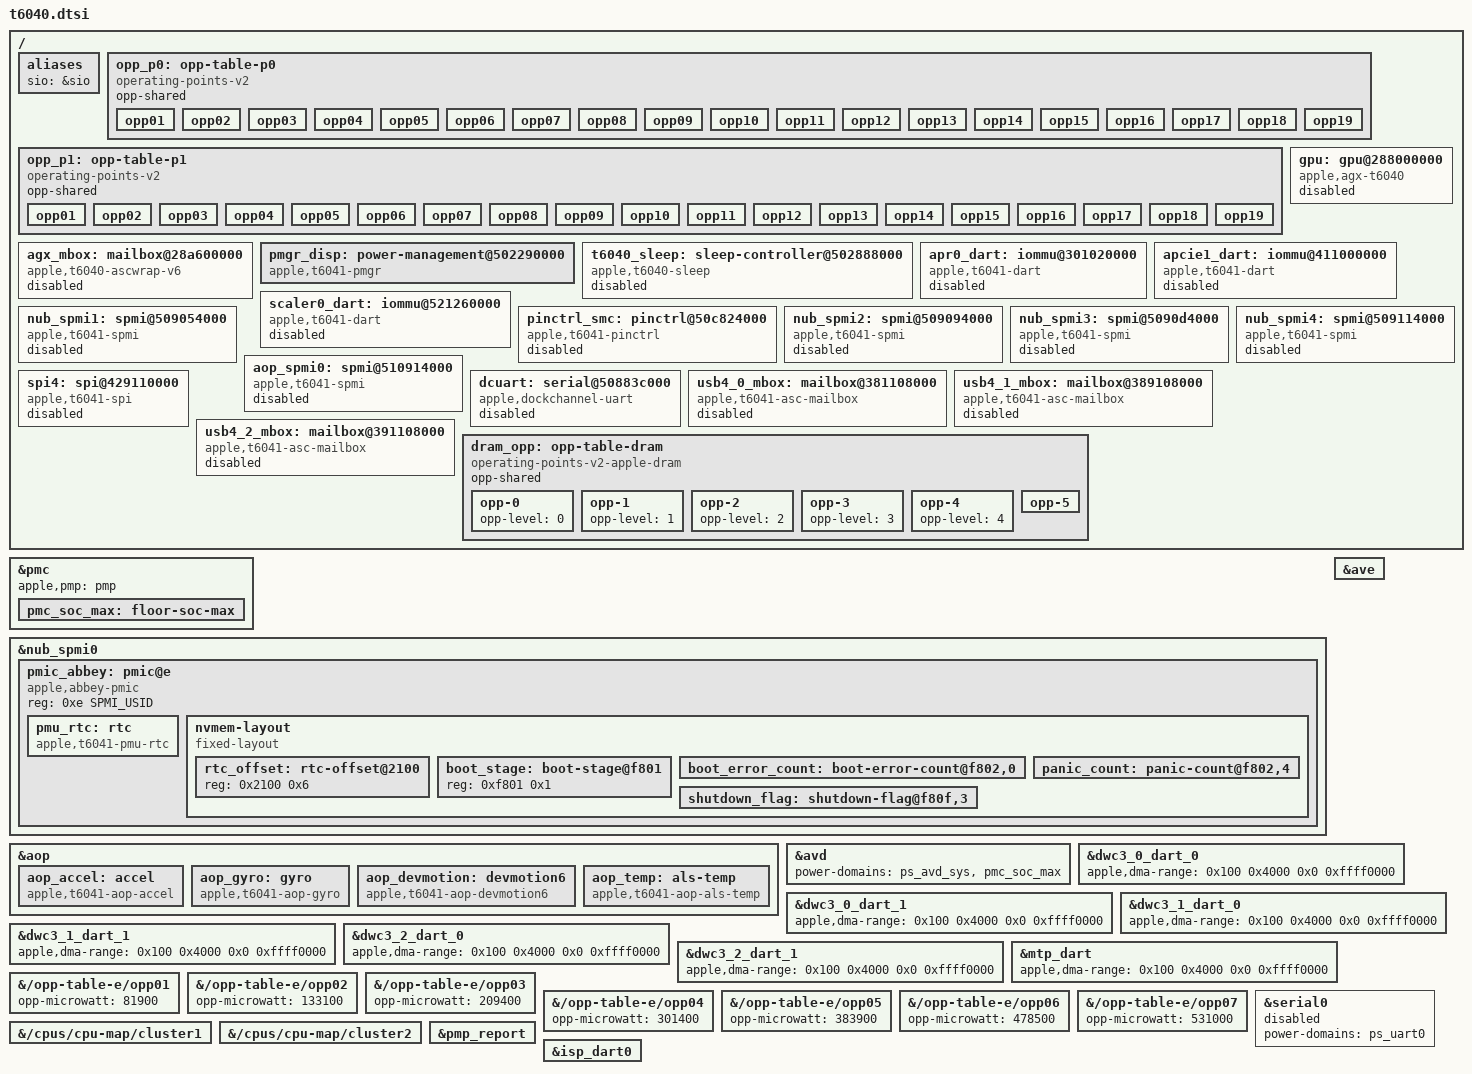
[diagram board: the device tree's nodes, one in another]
// SPDX-License-Identifier: GPL-2.0+ OR MIT
/*
 * Apple T6040 "M4 Pro" SoC
 *
 * Copyright The Asahi Linux Contributors
 */

#include "t604x.dtsi"

/* Blocks and properties the T6041 tree does not describe yet. */
/ {
	aliases {
		sio = &sio;
	};

	opp_p0: opp-table-p0 {
		compatible = "operating-points-v2";
		opp-shared;

		opp01 {
			opp-hz = /bits/ 64 <1260000000>;
			opp-level = <1>;
			opp-microwatt = <513000>;
		};
		opp02 {
			opp-hz = /bits/ 64 <1512000000>;
			opp-level = <2>;
			opp-microwatt = <715000>;
		};
		opp03 {
			opp-hz = /bits/ 64 <1800000000>;
			opp-level = <3>;
			opp-microwatt = <907500>;
		};
		opp04 {
			opp-hz = /bits/ 64 <2088000000>;
			opp-level = <4>;
			opp-microwatt = <1158200>;
		};
		opp05 {
			opp-hz = /bits/ 64 <2352000000>;
			opp-level = <5>;
			opp-microwatt = <1494500>;
		};
		opp06 {
			opp-hz = /bits/ 64 <2616000000>;
			opp-level = <6>;
			opp-microwatt = <1782600>;
		};
		opp07 {
			opp-hz = /bits/ 64 <2868000000>;
			opp-level = <7>;
			opp-microwatt = <2209600>;
		};
		opp08 {
			opp-hz = /bits/ 64 <3096000000>;
			opp-level = <8>;
			opp-microwatt = <2636700>;
		};
		opp09 {
			opp-hz = /bits/ 64 <3300000000>;
			opp-level = <9>;
			opp-microwatt = <3247200>;
		};
		opp10 {
			opp-hz = /bits/ 64 <3468000000>;
			opp-level = <10>;
			opp-microwatt = <3668700>;
		};
		opp11 {
			opp-hz = /bits/ 64 <3624000000>;
			opp-level = <11>;
			opp-microwatt = <4128200>;
		};
		opp12 {
			opp-hz = /bits/ 64 <3756000000>;
			opp-level = <12>;
			opp-microwatt = <4819300>;
		};
		opp13 {
			opp-hz = /bits/ 64 <3852000000>;
			opp-level = <13>;
			opp-microwatt = <4977700>;
		};
		opp14 {
			opp-hz = /bits/ 64 <3924000000>;
			opp-level = <14>;
			opp-microwatt = <5315900>;
		};
		opp15 {
			opp-hz = /bits/ 64 <3996000000>;
			opp-level = <15>;
			opp-microwatt = <5575900>;
		};
		opp16 {
			opp-hz = /bits/ 64 <4044000000>;
			opp-level = <16>;
			opp-microwatt = <5773400>;
		};
		opp17 {
			opp-hz = /bits/ 64 <4104000000>;
			opp-level = <17>;
			opp-microwatt = <5969200>;
		};
		opp18 {
			opp-hz = /bits/ 64 <4416000000>;
			opp-level = <18>;
			opp-microwatt = <8274900>;
		};
		opp19 {
			opp-hz = /bits/ 64 <4512000000>;
			opp-level = <19>;
			opp-microwatt = <9256900>;
		};
	};

	opp_p1: opp-table-p1 {
		compatible = "operating-points-v2";
		opp-shared;

		opp01 {
			opp-hz = /bits/ 64 <1260000000>;
			opp-level = <1>;
			opp-microwatt = <561800>;
		};
		opp02 {
			opp-hz = /bits/ 64 <1512000000>;
			opp-level = <2>;
			opp-microwatt = <772500>;
		};
		opp03 {
			opp-hz = /bits/ 64 <1800000000>;
			opp-level = <3>;
			opp-microwatt = <988900>;
		};
		opp04 {
			opp-hz = /bits/ 64 <2088000000>;
			opp-level = <4>;
			opp-microwatt = <1302300>;
		};
		opp05 {
			opp-hz = /bits/ 64 <2352000000>;
			opp-level = <5>;
			opp-microwatt = <1644100>;
		};
		opp06 {
			opp-hz = /bits/ 64 <2616000000>;
			opp-level = <6>;
			opp-microwatt = <2003700>;
		};
		opp07 {
			opp-hz = /bits/ 64 <2868000000>;
			opp-level = <7>;
			opp-microwatt = <2349000>;
		};
		opp08 {
			opp-hz = /bits/ 64 <3096000000>;
			opp-level = <8>;
			opp-microwatt = <2723000>;
		};
		opp09 {
			opp-hz = /bits/ 64 <3300000000>;
			opp-level = <9>;
			opp-microwatt = <3333200>;
		};
		opp10 {
			opp-hz = /bits/ 64 <3468000000>;
			opp-level = <10>;
			opp-microwatt = <3711900>;
		};
		opp11 {
			opp-hz = /bits/ 64 <3624000000>;
			opp-level = <11>;
			opp-microwatt = <4129900>;
		};
		opp12 {
			opp-hz = /bits/ 64 <3756000000>;
			opp-level = <12>;
			opp-microwatt = <4666300>;
		};
		opp13 {
			opp-hz = /bits/ 64 <3852000000>;
			opp-level = <13>;
			opp-microwatt = <4881000>;
		};
		opp14 {
			opp-hz = /bits/ 64 <3924000000>;
			opp-level = <14>;
			opp-microwatt = <5176700>;
		};
		opp15 {
			opp-hz = /bits/ 64 <3996000000>;
			opp-level = <15>;
			opp-microwatt = <5306500>;
		};
		opp16 {
			opp-hz = /bits/ 64 <4044000000>;
			opp-level = <16>;
			opp-microwatt = <5618900>;
		};
		opp17 {
			opp-hz = /bits/ 64 <4104000000>;
			opp-level = <17>;
			opp-microwatt = <5843100>;
		};
		opp18 {
			opp-hz = /bits/ 64 <4416000000>;
			opp-level = <18>;
			opp-microwatt = <8075300>;
		};
		opp19 {
			opp-hz = /bits/ 64 <4512000000>;
			opp-level = <19>;
			opp-microwatt = <8949200>;
		};
	};

	/* Named after its sgx range: the coprocessor range is the mailbox node's too. */
	gpu: gpu@288000000 {
		compatible = "apple,agx-t6040";
		reg = <0x2 0x8a600000 0x0 0x88000>,
		      <0x2 0x88000000 0x0 0x3758000>;
		reg-names = "asc", "sgx";
		mboxes = <&agx_mbox>;
		power-domains = <&pmp_gfx>;
		apple,clpc = <&clpc>;
		status = "disabled";
	};

	agx_mbox: mailbox@28a600000 {
		compatible = "apple,t6040-ascwrap-v6";
		reg = <0x2 0x8a600000 0x0 0x88000>,
		      <0x2 0x8a050000 0x0 0x8>;
		reg-names = "wrapper", "iop-vbar";
		interrupt-parent = <&aic>;
		interrupts = <AIC_IRQ 1501 IRQ_TYPE_LEVEL_HIGH>,
			     <AIC_IRQ 1504 IRQ_TYPE_LEVEL_HIGH>;
		interrupt-names = "send-empty", "recv-not-empty";
		apple,firmware-role = "GFX";
		power-domains = <&ps_gfx>;
		#mbox-cells = <0>;
		status = "disabled";
	};

	pmgr_disp: power-management@502290000 {
		compatible = "apple,t6041-pmgr", "apple,t8103-pmgr", "syscon", "simple-mfd";
		reg = <0x5 0x02290000 0x0 0x4000>;
		/* DISP_CPU's power word takes non-posted accesses (nGnRnE). */
		nonposted-mmio;
		#address-cells = <1>;
		#size-cells = <1>;
	};

	t6040_sleep: sleep-controller@502888000 {
		compatible = "apple,t6040-sleep";
		/*
		 * The SoC blocks the commit and wake
		 * write, all shared read/write with their owning drivers and
		 * touched only once no blocker remains:
		 *   cpu-start   pmgr reg0 + 0x88000 (misc-cores): CPU start/stop
		 *   wdt         the AON watchdog, the sleep's WD2 safety net
		 *   cluster     0x502820000: the three CPU complexes E/P0/P1
		 *   pwrgate     0x50282c000: wake + CPM retention voters
		 *   clkgen      0x500000000: the clk-mux park words
		 *   spmi        0x509014000: the PMU boot-stage + NOTIFY + go-hib
		 *   spmi-a0     0x509188000: the second SPMI NOTIFY
		 *   mastermini  0x508900000: the S2R timer at +0x4000 (the commit)
		 *   soc-east    0x502280000: SOC-East page, retention + east power words
		 *   soc-ps      0x502800000: SOC page, the west axi2af power words
		 *   wake        0x508004000: the S2R control + wake masks/status
		 * The handler refuses before touching any of them.
		 */
		reg = <0x5 0x02888000 0x0 0x20>,
		      <0x5 0x0836c000 0x0 0x4000>,
		      <0x5 0x02820000 0x0 0x20>,
		      <0x5 0x0282c000 0x0 0x1000>,
		      <0x5 0x00000000 0x0 0x80000>,
		      <0x5 0x09014000 0x0 0x1000>,
		      <0x5 0x09188000 0x0 0x1000>,
		      <0x5 0x08900000 0x0 0x8000>,
		      <0x5 0x02280000 0x0 0xd000>,
		      <0x5 0x02800000 0x0 0x9000>,
		      <0x5 0x08004000 0x0 0x1000>;
		reg-names = "cpu-start", "wdt", "cluster", "pwrgate",
			    "clkgen", "spmi", "spmi-a0", "mastermini",
			    "soc-east", "soc-ps", "wake";
		/*
		 * ADT pmgr device-check-ps-b4-sleep (check-ps-b4-sleep = 0x1f): per
		 * display pipe its CPU and its last sub-block, 8 bytes apart.
		 */
		apple,check-ps-b4-sleep = <&pmgr_disp 0x0 0x58>, <&pmgr_aux 0x350 0x388>,
					  <&pmgr_aux 0x4a0 0x4d8>, <&pmgr_aux 0x4f0 0x528>,
					  <&pmgr_aux 0x2e8 0x320>;
		apple,check-ps-b4-sleep-names = "disp", "dispext0", "dispext1", "dispext2",
						"dispext3";
		/*
		 * apple,apcie, for the sleep of ANS's storage PCIe link (two ST lanes
		 * and a shared PHY), comes from the boot loader. From the ADT's
		 * /arm-io/apcie0 it adds it here and puts the axi2af, cio3pll, clkgen,
		 * phy-block and phy-ip windows and the apple,tunable-* arrays on the
		 * internal PCIe host (apple,t6020-pcie, the one with an "rc"
		 * reg-name), in the single-lane T8140 shape. It leaves a node that
		 * already has apple,apcie alone, so this tree must give neither
		 * apple,apcie nor an apcie-storage node. Without it a sleep with ANS
		 * stopped is refused, and suspend-to-idle stays the default. The ST
		 * power words (ps_ans, ps_apcie_st0/st1, ps_apcie_sys_st0/st1) are in
		 * SOC-East and are driven through the soc-east window.
		 */
		/* Only on a board whose sleep has been tested. */
		status = "disabled";
	};
};

&pmc {
	/*
	 * The SoC rail at its highest state. The video encoder runs on
	 * the fabric clock and encodes at less than half speed below it.
	 */
	pmc_soc_max: floor-soc-max {
		label = "soc-max";
		#power-domain-cells = <0>;
		apple,rail = <1>;
		apple,level = <2>;
	};
};

&nub_spmi0 {
	pmic_abbey: pmic@e {
		compatible = "apple,abbey-pmic", "apple,spmi-nvmem";
		reg = <0xe SPMI_USID>;

		pmu_rtc: rtc {
			compatible = "apple,t6041-pmu-rtc";
			interrupt-parent = <&nub_spmi0>;
			interrupts = <2 IRQ_TYPE_EDGE_RISING>;
			nvmem-cells = <&rtc_offset>;
			nvmem-cell-names = "rtc_offset";
			wakeup-source;
		};

		nvmem-layout {
			compatible = "fixed-layout";
			#address-cells = <1>;
			#size-cells = <1>;

			rtc_offset: rtc-offset@2100 {
				reg = <0x2100 0x6>;
			};

			boot_stage: boot-stage@f801 {
				reg = <0xf801 0x1>;
			};

			boot_error_count: boot-error-count@f802,0 {
				reg = <0xf802 0x1>;
				bits = <0 4>;
			};

			panic_count: panic-count@f802,4 {
				reg = <0xf802 0x1>;
				bits = <4 4>;
			};

			shutdown_flag: shutdown-flag@f80f,3 {
				reg = <0xf80f 0x1>;
				bits = <3 1>;
			};
		};
	};
};

&aop {
	/* The calibration properties come from the bootloader. */
	aop_accel: accel {
		compatible = "apple,t6041-aop-accel", "apple,aop-accel";
	};

	aop_gyro: gyro {
		compatible = "apple,t6041-aop-gyro", "apple,aop-gyro";
	};

	aop_devmotion: devmotion6 {
		compatible = "apple,t6041-aop-devmotion6", "apple,aop-devmotion6";
	};

	aop_temp: als-temp {
		compatible = "apple,t6041-aop-als-temp", "apple,aop-als-temp";
	};
};

/ {
	apr0_dart: iommu@301020000 {
		compatible = "apple,t6041-dart", "apple,t8110-dart";
		reg = <0x3 0x01020000 0x0 0xc000>;
		#iommu-cells = <1>;
		apple,dma-range = <0x100 0x0 0x300 0x0>;
		interrupt-parent = <&aic>;
		interrupts = <AIC_IRQ 1959 IRQ_TYPE_LEVEL_HIGH>;
		power-domains = <&ps_scodec>;
		status = "disabled";
	};

	apcie1_dart: iommu@411000000 {
		compatible = "apple,t6041-dart", "apple,t8110-dart";
		reg = <0x4 0x11000000 0x0 0x20000>;
		#iommu-cells = <1>;
		interrupt-parent = <&aic>;
		interrupts = <AIC_IRQ 1733 IRQ_TYPE_LEVEL_HIGH>;
		status = "disabled";
	};

	scaler0_dart: iommu@521260000 {
		compatible = "apple,t6041-dart", "apple,t8110-dart";
		reg = <0x5 0x21260000 0x0 0xc000>;
		#iommu-cells = <1>;
		apple,dma-range = <0x100 0x0 0x300 0x0>;
		interrupt-parent = <&aic>;
		interrupts = <AIC_IRQ 1548 IRQ_TYPE_LEVEL_HIGH>;
		power-domains = <&ps_msr0_dart>;
		status = "disabled";
	};

	pinctrl_smc: pinctrl@50c824000 {
		compatible = "apple,t6041-pinctrl", "apple,t8103-pinctrl";
		reg = <0x5 0x0c824000 0x0 0x4000>;
		clocks = <&clkref>;
		gpio-controller;
		#gpio-cells = <2>;
		gpio-ranges = <&pinctrl_smc 0 0 24>;
		apple,npins = <24>;
		interrupt-controller;
		#interrupt-cells = <2>;
		interrupt-parent = <&aic>;
		interrupts = <AIC_IRQ 985 IRQ_TYPE_LEVEL_HIGH>,
			     <AIC_IRQ 986 IRQ_TYPE_LEVEL_HIGH>,
			     <AIC_IRQ 987 IRQ_TYPE_LEVEL_HIGH>,
			     <AIC_IRQ 988 IRQ_TYPE_LEVEL_HIGH>,
			     <AIC_IRQ 989 IRQ_TYPE_LEVEL_HIGH>,
			     <AIC_IRQ 990 IRQ_TYPE_LEVEL_HIGH>,
			     <AIC_IRQ 991 IRQ_TYPE_LEVEL_HIGH>;
		/* Coprocessor pins and interrupt groups need an ownership handoff. */
		status = "disabled";
	};

	nub_spmi1: spmi@509054000 {
		compatible = "apple,t6041-spmi", "apple,t8103-spmi";
		reg = <0x5 0x09054000 0x0 0x100>;
		#address-cells = <2>;
		#size-cells = <0>;
		power-domains = <&ps_nub_spmi1>;
		status = "disabled";
	};

	nub_spmi2: spmi@509094000 {
		compatible = "apple,t6041-spmi", "apple,t8103-spmi";
		reg = <0x5 0x09094000 0x0 0x100>;
		#address-cells = <2>;
		#size-cells = <0>;
		power-domains = <&ps_nub_spmi2>;
		status = "disabled";
	};

	nub_spmi3: spmi@5090d4000 {
		compatible = "apple,t6041-spmi", "apple,t8103-spmi";
		reg = <0x5 0x090d4000 0x0 0x100>;
		#address-cells = <2>;
		#size-cells = <0>;
		power-domains = <&ps_nub_spmi3>;
		status = "disabled";
	};

	nub_spmi4: spmi@509114000 {
		compatible = "apple,t6041-spmi", "apple,t8103-spmi";
		reg = <0x5 0x09114000 0x0 0x100>;
		#address-cells = <2>;
		#size-cells = <0>;
		power-domains = <&ps_nub_spmi4>;
		status = "disabled";
	};

	aop_spmi0: spmi@510914000 {
		compatible = "apple,t6041-spmi", "apple,t8103-spmi";
		reg = <0x5 0x10914000 0x0 0x100>;
		#address-cells = <2>;
		#size-cells = <0>;
		#interrupt-cells = <2>;
		interrupt-controller;
		interrupt-parent = <&aic>;
		interrupts = <AIC_IRQ 738 IRQ_TYPE_LEVEL_HIGH>;
		status = "disabled";
	};

	spi4: spi@429110000 {
		compatible = "apple,t6041-spi", "apple,t8103-spi";
		reg = <0x4 0x29110000 0x0 0x4000>;
		interrupt-parent = <&aic>;
		interrupts = <AIC_IRQ 1571 IRQ_TYPE_LEVEL_HIGH>;
		clocks = <&clkref>;
		power-domains = <&ps_spi4>;
		#address-cells = <1>;
		#size-cells = <0>;
		/* Panel/TCON control belongs to the display firmware. */
		status = "disabled";
	};

	/*
	 * The DebugUSB DockChannel serial channel. Binding it disturbs the
	 * speaker amplifiers (I2C timeouts, TDM clock faults), so it stays
	 * disabled outside the tether variant.
	 */
	dcuart: serial@50883c000 {
		compatible = "apple,dockchannel-uart";
		reg = <0x5 0x0883c000 0x0 0x4000>,
		      <0x5 0x08838000 0x0 0x4000>,
		      <0x5 0x0880c000 0x0 0x4000>;
		reg-names = "data", "config", "irq";
		interrupt-parent = <&aic>;
		interrupts = <AIC_IRQ 360 IRQ_TYPE_LEVEL_HIGH>;
		apple,channel = <2>;
		apple,sw-drain;
		status = "disabled";
	};

	/* ACIO 0 remains disabled until its host-router handoff is supported. */
	usb4_0_mbox: mailbox@381108000 {
		compatible = "apple,t6041-asc-mailbox", "apple,asc-mailbox-v4";
		reg = <0x3 0x81108000 0x0 0x4000>;
		interrupt-parent = <&aic>;
		interrupts = <AIC_IRQ 934 IRQ_TYPE_LEVEL_HIGH>,
			     <AIC_IRQ 935 IRQ_TYPE_LEVEL_HIGH>,
			     <AIC_IRQ 936 IRQ_TYPE_LEVEL_HIGH>,
			     <AIC_IRQ 937 IRQ_TYPE_LEVEL_HIGH>;
		interrupt-names = "send-empty", "send-not-empty",
				  "recv-empty", "recv-not-empty";
		#mbox-cells = <0>;
		power-domains = <&ps_atc0_cio>;
		status = "disabled";
	};

	/* ACIO 1 remains disabled until its host-router handoff is supported. */
	usb4_1_mbox: mailbox@389108000 {
		compatible = "apple,t6041-asc-mailbox", "apple,asc-mailbox-v4";
		reg = <0x3 0x89108000 0x0 0x4000>;
		interrupt-parent = <&aic>;
		interrupts = <AIC_IRQ 944 IRQ_TYPE_LEVEL_HIGH>,
			     <AIC_IRQ 945 IRQ_TYPE_LEVEL_HIGH>,
			     <AIC_IRQ 946 IRQ_TYPE_LEVEL_HIGH>,
			     <AIC_IRQ 947 IRQ_TYPE_LEVEL_HIGH>;
		interrupt-names = "send-empty", "send-not-empty",
				  "recv-empty", "recv-not-empty";
		#mbox-cells = <0>;
		power-domains = <&ps_atc1_cio>;
		status = "disabled";
	};

	/* ACIO 2 remains disabled until its host-router handoff is supported. */
	usb4_2_mbox: mailbox@391108000 {
		compatible = "apple,t6041-asc-mailbox", "apple,asc-mailbox-v4";
		reg = <0x3 0x91108000 0x0 0x4000>;
		interrupt-parent = <&aic>;
		interrupts = <AIC_IRQ 954 IRQ_TYPE_LEVEL_HIGH>,
			     <AIC_IRQ 955 IRQ_TYPE_LEVEL_HIGH>,
			     <AIC_IRQ 956 IRQ_TYPE_LEVEL_HIGH>,
			     <AIC_IRQ 957 IRQ_TYPE_LEVEL_HIGH>;
		interrupt-names = "send-empty", "send-not-empty",
				  "recv-empty", "recv-not-empty";
		#mbox-cells = <0>;
		power-domains = <&ps_atc2_cio>;
		status = "disabled";
	};

};

&avd {
	power-domains = <&ps_avd_sys>, <&pmc_soc_max>;
	power-domain-names = "core", "perf";
};

&ave {
	power-domains = <&ps_venc0_dma>, <&ps_venc0_pipe4>,
			<&ps_venc0_pipe5>, <&ps_venc0_me0>, <&ps_venc0_me1>,
			<&pmc_soc_max>;
	power-domain-names = "dma", "pipe4", "pipe5", "me0", "me1", "perf";
};

&dwc3_0_dart_0 {
	apple,dma-range = <0x100 0x4000 0x0 0xffff0000>;
};

&dwc3_0_dart_1 {
	apple,dma-range = <0x100 0x4000 0x0 0xffff0000>;
};

&dwc3_1_dart_0 {
	apple,dma-range = <0x100 0x4000 0x0 0xffff0000>;
};

&dwc3_1_dart_1 {
	apple,dma-range = <0x100 0x4000 0x0 0xffff0000>;
};

&dwc3_2_dart_0 {
	apple,dma-range = <0x100 0x4000 0x0 0xffff0000>;
};

&dwc3_2_dart_1 {
	apple,dma-range = <0x100 0x4000 0x0 0xffff0000>;
};

&mtp_dart {
	apple,dma-range = <0x100 0x4000 0x0 0xffff0000>;
};

&{/opp-table-e/opp01} {
	opp-microwatt = <81900>;
};

&{/opp-table-e/opp02} {
	opp-microwatt = <133100>;
};

&{/opp-table-e/opp03} {
	opp-microwatt = <209400>;
};

&{/opp-table-e/opp04} {
	opp-microwatt = <301400>;
};

&{/opp-table-e/opp05} {
	opp-microwatt = <383900>;
};

&{/opp-table-e/opp06} {
	opp-microwatt = <478500>;
};

&{/opp-table-e/opp07} {
	opp-microwatt = <531000>;
};

&serial0 {
	power-domains = <&ps_uart0>;
	status = "disabled";
};

&pmc {
	apple,pmp = <&pmp>;
};

#include "t6040-pmgr.dtsi"
#include "t6040-peripherals.dtsi"

/* The M4 Pro has five cores in each P cluster. */
/delete-node/ &cpu_p05;
/delete-node/ &cpu_p15;

&{/cpus/cpu-map/cluster1} {
	/delete-node/ core5;
};

&{/cpus/cpu-map/cluster2} {
	/delete-node/ core5;
};

/*
 * DRAM interface class: width and maximum rate are inferred from topology
 * and the published bandwidth class. Lower-state rates remain unqualified.
 * State IDs below describe firmware DCS states, not PMGR codes.
 */
/ {
	dram_opp: opp-table-dram {
		compatible = "operating-points-v2-apple-dram";
		opp-shared;

		opp-0 {
			opp-level = <0>;
		};

		opp-1 {
			opp-level = <1>;
		};

		opp-2 {
			opp-level = <2>;
		};

		opp-3 {
			opp-level = <3>;
		};

		opp-4 {
			opp-level = <4>;
		};

		opp-5 {
			opp-level = <5>;
			opp-hz = /bits/ 64 <4266666667>;
			apple,data-rate = /bits/ 64 <8533333333>;
		};
	};
};

&pmp_report {
	operating-points-v2 = <&dram_opp>;
	apple,dram-type = "lpddr5";
	apple,data-bus-width = <256>;
	apple,dcs-state-count = <6>;
	apple,peak-bandwidth-bytes-per-second = /bits/ 64 <273066666656>;
	apple,bandwidth-class-bytes-per-second = /bits/ 64 <273000000000>;
};

/*
 * The ISP DART's address filter, from the ADT's dart-isp0 dapf-instance-0
 * (its sixth reg window): the firmware's PMGR, PMP and DSID windows, in the
 * ADT's order. The filter goes off with the ISP system domain and is
 * written back when the DART powers up again, so the ISP firmware can start
 * again after the ISP has been powered down between streams.
 */
&isp_dart0 {
	reg = <0x5 0x828c0000 0x0 0xc000>,
	      <0x5 0x828d0000 0x0 0x4000>;
	reg-names = "dart", "dapf";
	apple,dapf-ranges = /bits/ 64 <0x502284000 0x50228402b
				     0x502880000 0x502887fff
				     0x500e3c000 0x500e3c003
				     0x51062c000 0x510648003
				     0x485660000 0x485660003
				     0x220004000 0x2201d62fc
				     0x222004000 0x2221d62fc
				     0x224004000 0x2241d62fc
				     0x226004000 0x2261d62fc
				     0x504824000 0x504824004
				     0x5003c0000 0x5003e4000>;
};

#include "t6040-usb4.dtsi"
